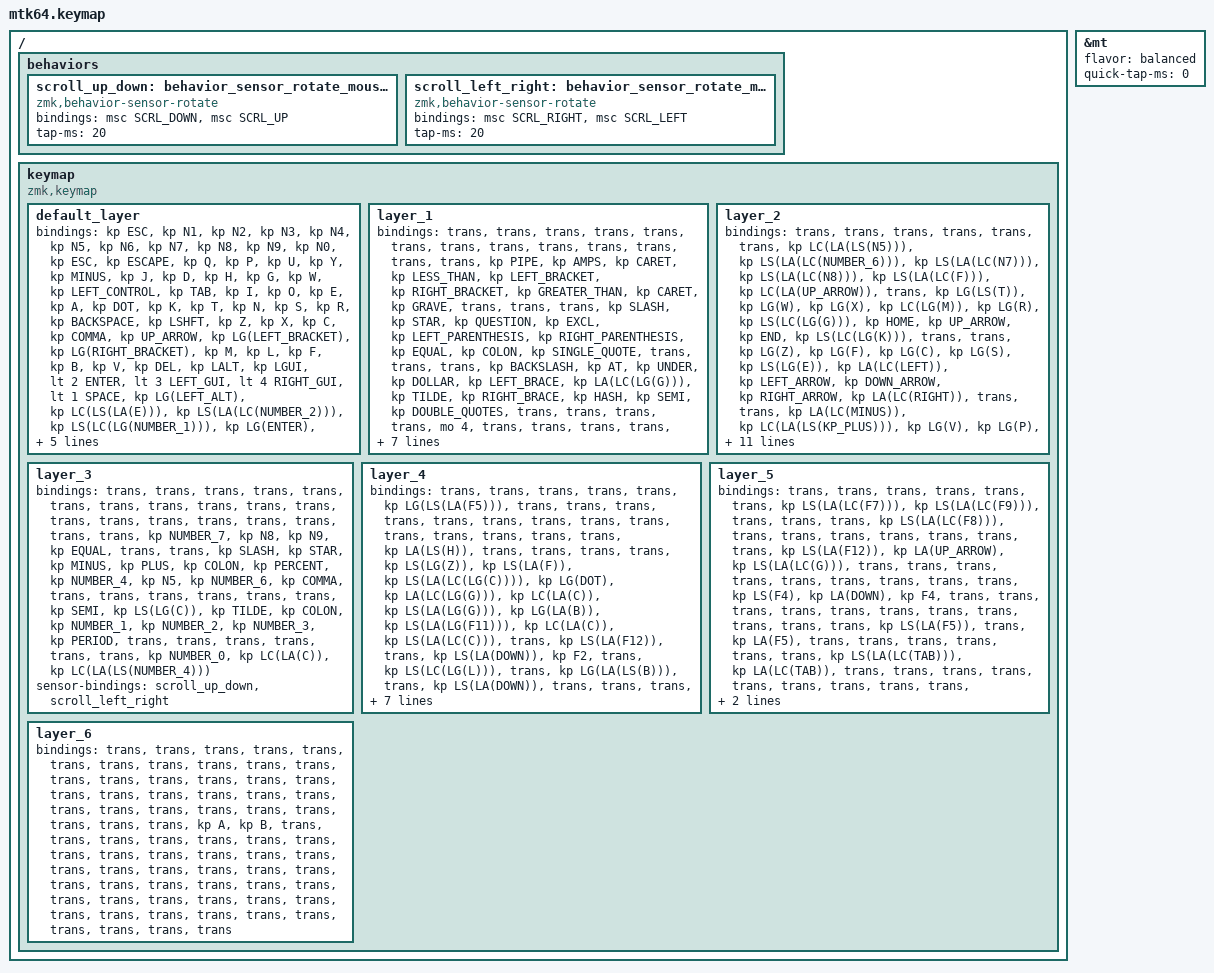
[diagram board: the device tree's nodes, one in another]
#include "keycode_japanese.h"
#include <behaviors.dtsi>
#include <dt-bindings/zmk/keys.h>
#include <dt-bindings/zmk/pointing.h>

// スクロール量の設定

#define ZMK_POINTING_DEFAULT_SCRL_VAL 100

&mt {
    flavor = "balanced";
    quick-tap-ms = <0>;
};

/ {
    behaviors {
        // 垂直スクロール用のbehaviorの設定

        scroll_up_down: behavior_sensor_rotate_mouse_wheel_down_up {
            compatible = "zmk,behavior-sensor-rotate";
            #sensor-binding-cells = <0>;
            bindings = <&msc SCRL_DOWN>, <&msc SCRL_UP>;

            tap-ms = <20>; // スクロールのタップ時間
        };

        // 水平スクロール用のbehaviorの設定

        scroll_left_right: behavior_sensor_rotate_mouse_wheel_right_left {
            compatible = "zmk,behavior-sensor-rotate";
            #sensor-binding-cells = <0>;
            bindings = <&msc SCRL_RIGHT>, <&msc SCRL_LEFT>;

            tap-ms = <20>; // スクロールのタップ時間
        };
    };
};

/ {
    keymap {
        compatible = "zmk,keymap";

        default_layer {
            bindings = <
&kp ESC  &kp N1  &kp N2  &kp N3  &kp N4  &kp N5  &kp N6  &kp N7  &kp N8  &kp N9  &kp N0  &kp ESC  &kp ESCAPE  &kp Q  &kp P  &kp U  &kp Y  &kp MINUS  &kp J  &kp D  &kp H  &kp G  &kp W  &kp LEFT_CONTROL  &kp TAB  &kp I  &kp O  &kp E  &kp A  &kp DOT  &kp K  &kp T  &kp N  &kp S  &kp R  &kp BACKSPACE  &kp LSHFT  &kp Z  &kp X  &kp C  &kp COMMA  &kp UP_ARROW  &kp LG(LEFT_BRACKET)  &kp LG(RIGHT_BRACKET)  &kp M  &kp L  &kp F  &kp B  &kp V  &kp DEL  &kp LALT  &kp LGUI  &lt 2 ENTER  &lt 3 LEFT_GUI  &lt 4 RIGHT_GUI  &lt 1 SPACE  &kp LG(LEFT_ALT)  &kp LC(LS(LA(E)))  &kp LS(LA(LC(NUMBER_2)))  &kp LS(LC(LG(NUMBER_1)))  &kp LG(ENTER)  &lt 5 LS(ENTER)  &kp ENTER  &tog 2  &kp LG(F12)  &kp LG(LA(LC(LS(X))))  &mo 1  &mo 2  &mo 3  &mo 1  &mo 2  &mo 3  &mo 1  &mo 2  &mo 3
            >;

            sensor-bindings = <&scroll_left_right>, <&scroll_up_down>;
        };

        layer_1 {
            bindings = <
&trans  &trans  &trans  &trans  &trans  &trans  &trans  &trans  &trans  &trans  &trans  &trans  &trans  &kp PIPE  &kp AMPS  &kp CARET  &kp LESS_THAN  &kp LEFT_BRACKET  &kp RIGHT_BRACKET  &kp GREATER_THAN  &kp CARET  &kp GRAVE  &trans  &trans  &trans  &kp SLASH  &kp STAR  &kp QUESTION  &kp EXCL  &kp LEFT_PARENTHESIS  &kp RIGHT_PARENTHESIS  &kp EQUAL  &kp COLON  &kp SINGLE_QUOTE  &trans  &trans  &trans  &kp BACKSLASH  &kp AT  &kp UNDER  &kp DOLLAR  &kp LEFT_BRACE  &kp LA(LC(LG(G)))  &kp TILDE  &kp RIGHT_BRACE  &kp HASH  &kp SEMI  &kp DOUBLE_QUOTES  &trans  &trans  &trans  &trans  &mo 4  &trans  &trans  &trans  &trans  &trans  &kp LG(N0)  &kp LS(LA(LC(NUMBER_4)))  &trans  &trans  &trans  &trans  &trans  &trans  &trans  &trans  &trans  &trans  &trans  &trans  &trans  &trans  &trans
            >;

            sensor-bindings =
                <&inc_dec_kp LG(PLUS) LG(MINUS)>,
                <&scroll_left_right>;
        };

        layer_2 {
            bindings = <
&trans  &trans  &trans  &trans  &trans  &trans  &kp LC(LA(LS(N5)))  &kp LS(LA(LC(NUMBER_6)))  &kp LS(LA(LC(N7)))  &kp LS(LA(LC(N8)))  &kp LS(LA(LC(F)))  &kp LC(LA(UP_ARROW))  &trans  &kp LG(LS(T))  &kp LG(W)  &kp LG(X)  &kp LC(LG(M))  &kp LG(R)  &kp LS(LC(LG(G)))  &kp HOME  &kp UP_ARROW  &kp END  &kp LS(LC(LG(K)))  &trans  &trans  &kp LG(Z)  &kp LG(F)  &kp LG(C)  &kp LG(S)  &kp LS(LG(E))  &kp LA(LC(LEFT))  &kp LEFT_ARROW  &kp DOWN_ARROW  &kp RIGHT_ARROW  &kp LA(LC(RIGHT))  &trans  &trans  &kp LA(LC(MINUS))  &kp LC(LA(LS(KP_PLUS)))  &kp LG(V)  &kp LG(P)  &kp LG(SLASH)  &kp F12  &kp LC(LS(G))  &kp LG(LS(LA(C)))  &mkp MB1  &kp LG(LA(LC(LS(G))))  &mkp MB2  &kp LG(LS(LA(G)))  &trans  &mo 5  &trans  &trans  &trans  &kp LS(LC(TAB))  &kp LC(TAB)  &kp LS(LC(C))  &kp LC(UP_ARROW)  &trans  &trans  &trans  &trans  &trans  &trans  &kp LS(LG(C))  &kp LG(LA(LC(G)))  &trans  &trans  &trans  &trans  &trans  &trans  &trans  &trans  &trans
            >;

            sensor-bindings = <&inc_dec_kp TAB LC(TAB)>, <&scroll_up_down>;
        };

        layer_3 {
            bindings = <
&trans  &trans  &trans  &trans  &trans  &trans  &trans  &trans  &trans  &trans  &trans  &trans  &trans  &trans  &trans  &trans  &trans  &trans  &trans  &kp NUMBER_7  &kp N8  &kp N9  &kp EQUAL  &trans  &trans  &kp SLASH  &kp STAR  &kp MINUS  &kp PLUS  &kp COLON  &kp PERCENT  &kp NUMBER_4  &kp N5  &kp NUMBER_6  &kp COMMA  &trans  &trans  &trans  &trans  &trans  &trans  &kp SEMI  &kp LS(LG(C))  &kp TILDE  &kp COLON  &kp NUMBER_1  &kp NUMBER_2  &kp NUMBER_3  &kp PERIOD  &trans  &trans  &trans  &trans  &trans  &trans  &kp NUMBER_0  &kp LC(LA(C))  &kp LC(LA(LS(NUMBER_4)))
            >;

            sensor-bindings = <
                &scroll_up_down
                &scroll_left_right
            >;
        };

        layer_4 {
            bindings = <
&trans  &trans  &trans  &trans  &trans  &kp LG(LS(LA(F5)))  &trans  &trans  &trans  &trans  &trans  &trans  &trans  &trans  &trans  &trans  &trans  &trans  &trans  &trans  &kp LA(LS(H))  &trans  &trans  &trans  &trans  &kp LS(LG(Z))  &kp LS(LA(F))  &kp LS(LA(LC(LG(C))))  &kp LG(DOT)  &kp LA(LC(LG(G)))  &kp LC(LA(C))  &kp LS(LA(LG(G)))  &kp LG(LA(B))  &kp LS(LA(LG(F11)))  &kp LC(LA(C))  &kp LS(LA(LC(C)))  &trans  &kp LS(LA(F12))  &trans  &kp LS(LA(DOWN))  &kp F2  &trans  &kp LS(LC(LG(L)))  &trans  &kp LG(LA(LS(B)))  &trans  &kp LS(LA(DOWN))  &trans  &trans  &trans  &trans  &trans  &trans  &trans  &trans  &trans  &trans  &trans  &trans  &trans  &trans  &trans  &trans  &trans  &trans  &trans  &trans  &trans  &trans  &trans  &trans  &trans  &trans  &trans  &trans
            >;

            sensor-bindings =
                <&scroll_left_right>,
                <&inc_dec_kp LC(TAB) LS(LC(TAB))>;
        };

        layer_5 {
            bindings = <
&trans  &trans  &trans  &trans  &trans  &trans  &kp LS(LA(LC(F7)))  &kp LS(LA(LC(F9)))  &trans  &trans  &trans  &kp LS(LA(LC(F8)))  &trans  &trans  &trans  &trans  &trans  &trans  &trans  &kp LS(LA(F12))  &kp LA(UP_ARROW)  &kp LS(LA(LC(G)))  &trans  &trans  &trans  &trans  &trans  &trans  &trans  &trans  &trans  &kp LS(F4)  &kp LA(DOWN)  &kp F4  &trans  &trans  &trans  &trans  &trans  &trans  &trans  &trans  &trans  &trans  &trans  &kp LS(LA(F5))  &trans  &kp LA(F5)  &trans  &trans  &trans  &trans  &trans  &trans  &kp LS(LA(LC(TAB)))  &kp LA(LC(TAB))  &trans  &trans  &trans  &trans  &trans  &trans  &trans  &trans  &trans  &kp LS(LC(LG(L)))  &trans  &trans  &trans  &trans  &trans  &trans  &trans  &trans  &trans
            >;
        };

        layer_6 {
            bindings = <
&trans  &trans  &trans  &trans  &trans  &trans  &trans  &trans  &trans  &trans  &trans  &trans  &trans  &trans  &trans  &trans  &trans  &trans  &trans  &trans  &trans  &trans  &trans  &trans  &trans  &trans  &trans  &trans  &trans  &trans  &trans  &trans  &kp A  &kp B  &trans  &trans  &trans  &trans  &trans  &trans  &trans  &trans  &trans  &trans  &trans  &trans  &trans  &trans  &trans  &trans  &trans  &trans  &trans  &trans  &trans  &trans  &trans  &trans  &trans  &trans  &trans  &trans  &trans  &trans  &trans  &trans  &trans  &trans  &trans  &trans  &trans  &trans  &trans  &trans  &trans
            >;
        };
    };
};
